# MCXN947_cm33_core0 register map
Vendor: nxp.com; File version: 1.0
CPU: CM33 r2p0, little endian, MPU, FPU, VTOR, 3 interrupt priority bits
Registers are 32-bit, read-write, reset 0x0 unless marked. A register's access mark holds for its fields unless they carry their own. Offsets are from the block's base; [hi:lo] are bit positions; {n}, {i} and the like mark numbered series; 'fields as' and 'values as' point back to an identical list.

## PKC0
Base 0x4002B000
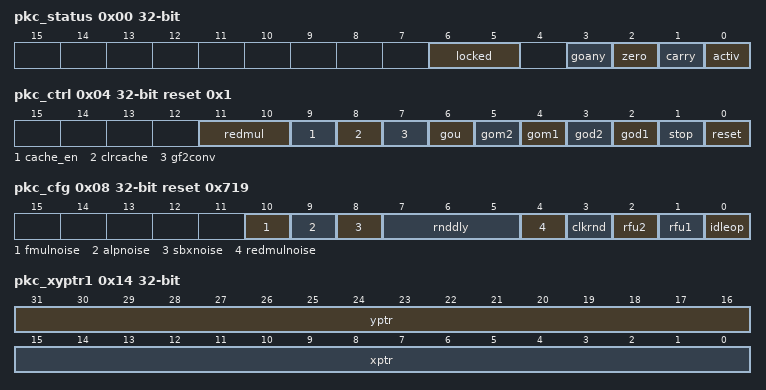
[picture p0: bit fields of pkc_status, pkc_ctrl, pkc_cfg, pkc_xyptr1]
0x00 pkc_status ro — Status register
  [6:5] locked — Parameter set locked: Indicates if parameter set is locked due to a pending calculation start or can be overwritten.
  [3] goany — Combined GO status flag: GOANY is set in case either PKC_CTRL.GOD1, GOD2, GOM1, GOM2 or GOU is set. The 1-to-0 transition of GOANY indicates that a calculation has been started and that a new GO bit can be set. If GOANY is cleared also all PKC_STATUS.LOCKED bits are cleared to indicate that the parameter set can be updated. GOANY is always '0' in case PKC_CTRL.RESET is set.
  [2] zero — Zero result flag: ZERO is set by the PKC at the end of a calculation in case the result of the calculation is equal zero. ZERO is updated for each PKC calculation mode, except for MUL1 (opcode 0x20) and MUL1_GF2 (opcode 0x24).
  [1] carry — Carry overflow flag: CARRY is set by the PKC at the end of a calculation in case
  [0] activ — PKC active: ACTIV=1 signals that a calculation is in progress or about to start. At the end of a calculation ACTIV is automatically reset to logic 0 in case no further GO bit is set. If the next PKC operation has been started by setting a GO bit during a calculation, ACTIV remains high. ACTIV is always '1' in case PKC_STATUS.GOANY is set. ACTIV is always '0' in case PKC_CTRL_RESET is set.
0x04 pkc_ctrl reset 0x1 — Control register
  [11:10] redmul — Reduced multiplier mode: REDMUL defines the operand width processed by the PKC coprocessor.
    0=fullsz (full size mode, 3 least significant bits of pointer and length are ignored, minimum supported length 0x0008); 1=VALUE_32bit (RFU Error Generated if selected); 2=VALUE_64bit (64-bit mode, 3 least significant bits of pointer and length are ignored, minimum supported length 0x0008); 3=VALUE_128bit (RFU Error Generated if selected)
  [9] cache_en — Enable universal pointer cache: If CACHE_EN=1 the cache for the universal pointer parameters is enabled. In case a parameter value is found in the cache (from a previous fetch) no DMA access is triggered. As such the amount of DMA accesses for the parameter fetch vary between 0 and 4. To further optimize the cache utilization not used parameters, e.g. XPTR for a plain addition (opcode 0x0A), could be defined equal to a used one (e.g. equal YPTR or RPTR) or a previously fetched parameter.
  [8] clrcache wo — Clear universal pointer cache: Invalidates the cache such that all previously fetched parameters are withdrawn and have to be fetched again via DMA accesses.
  [7] gf2conv — Convert to GF2 calculation modes: If GF2CONV is set operations are mapped to their GF(2) equivalent operation modes.
  [6] gou wo — Control bit to start pipe operation: If GOU is set PKC will start the pipe / L2 operation (parameter fetch & calculation) described in section 'PKC Universal Pointer Fetch Operation'.
  [5] gom2 wo — Control bit to start MC pattern using parameter set 2: If GOM2 is set PKC will start a MC pattern / L1 operation using parameter set 2 (PKC_MODE2, PKC_XYPTR2, PKC_ZRPTR2, PKC_LEN2).
  [4] gom1 wo — Control bit to start MC pattern using parameter set 1: If GOM1 is set PKC will start a MC pattern / L1 operation using parameter set 1 (PKC_MODE1, PKC_XYPTR1, PKC_ZRPTR1, PKC_LEN1).
  [3] god2 wo — Control bit to start direct operation using parameter set 2: If GOD2 is set PKC will start a direct / L0 operation using parameter set 2 (PKC_MODE2, PKC_XYPTR2, PKC_ZRPTR2, PKC_LEN2).
  [2] god1 wo — Control bit to start direct operation using parameter set 1: If GOD1 is set PKC will start a direct / L0 operation using parameter set 1 (PKC_MODE1, PKC_XYPTR1, PKC_ZRPTR1, PKC_LEN1).
  [1] stop — Freeze PKC calculation: STOP=1 freezes all PKC activity incl. RAM accesses and reduces the PKC power consumption to its minimum. The difference compared to the reset of the PKC is that a stopped calculation can be continued when STOP is released (reset to '0') again. The status flags are not affected by the STOP control bit.
  [0] reset — PKC reset control bit: RESET=1 enforces the PKC's reset state during which a calculation cannot be started and by which any ongoing calculation process is stopped. RESET can be set/cleared by the CPU in order to switch between PKC reset and calculation enable. RESET=1 is the default state after a chip reset.
0x08 pkc_cfg reset 0x719 — Configuration register
  [10] fmulnoise — Noise feature not available in this version (flag is don't care).
  [9] alpnoise — Noise feature not available in this version (flag is don't care).
  [8] sbxnoise — Noise feature not available in this version (flag is don't care).
  [7:5] rnddly — Random delay feature not available in this version (flag is don't care).
  [4] redmulnoise — Noise in reduced multiplier mode feature not available in this version (flag is don't care).
  [3] clkrnd — Clock randomization feature not available in this version (flag is don't care).
  [2] rfu2 — RFU
  [1] rfu1 — RFU
  [0] idleop — Idle operation feature not available in this version (flag is don't care).
0x10 pkc_mode1 — Mode register, parameter set 1
  [7:0] mode — Calculation Mode / MC Start address:
0x14 pkc_xyptr1 — X+Y pointer register, parameter set 1
  [31:16] yptr — Start address of Y operand in PKCRAM with byte granularity: Least significant bits are ignored depending on PKC_CTRL.REDMUL setting. Most significant bits are ignored depending on available PKCRAM size.
  [15:0] xptr — Start address of X operand in PKCRAM with byte granularity: Least significant bits are ignored depending on PKC_CTRL.REDMUL setting. Most significant bits are ignored depending on available PKCRAM size.
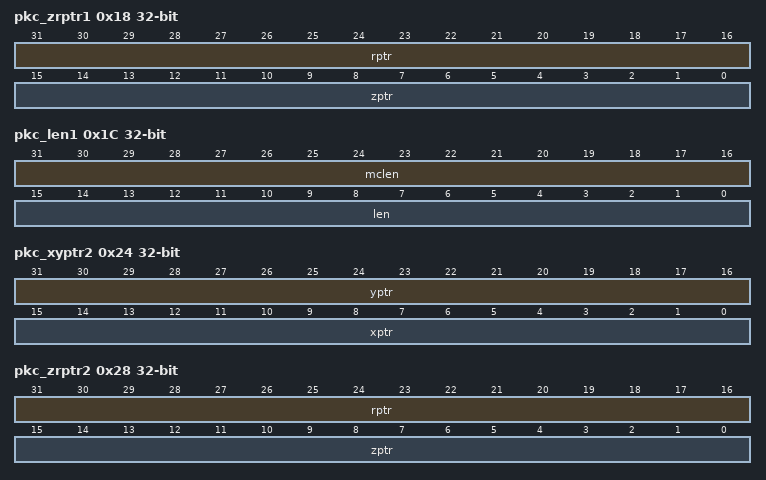
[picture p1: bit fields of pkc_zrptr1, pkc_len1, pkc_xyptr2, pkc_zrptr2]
0x18 pkc_zrptr1 — Z+R pointer register, parameter set 1
  [31:16] rptr — Start address of R result in PKCRAM with byte granularity: Least significant bits are ignored depending on PKC_CTRL.REDMUL setting. Most significant bits are ignored depending on available PKCRAM size.
  [15:0] zptr — Start address of Z operand in PKCRAM with byte granularity or constant for calculation modes using CONST:
0x1C pkc_len1 — Length register, parameter set 1
  [31:16] mclen — Loop counter for microcode pattern: MCLEN defines the length of the loop counter that can be used in L1 calculation mode, e.g. in MC opcode DecrTBNZ. For the hardcoded MC patterns Modular Multiplication (MC start address 0x00), Plain Multiplication (0x13), Plain Multiplication with Addition (0x1D) and Modular Reduction (0x33) MCLEN defines the length of the X operand in bytes.
  [15:0] len — Operand length: LEN defines the length of the operands and the result in bytes. The length of Y, Z and R depend furthermore on the selected calculation mode.
0x20 pkc_mode2 — Mode register, parameter set 2
  [7:0] mode — Calculation Mode / MC Start address:
0x24 pkc_xyptr2 — X+Y pointer register, parameter set 2
  fields as pkc_xyptr1
0x28 pkc_zrptr2 — Z+R pointer register, parameter set 2
  fields as pkc_zrptr1
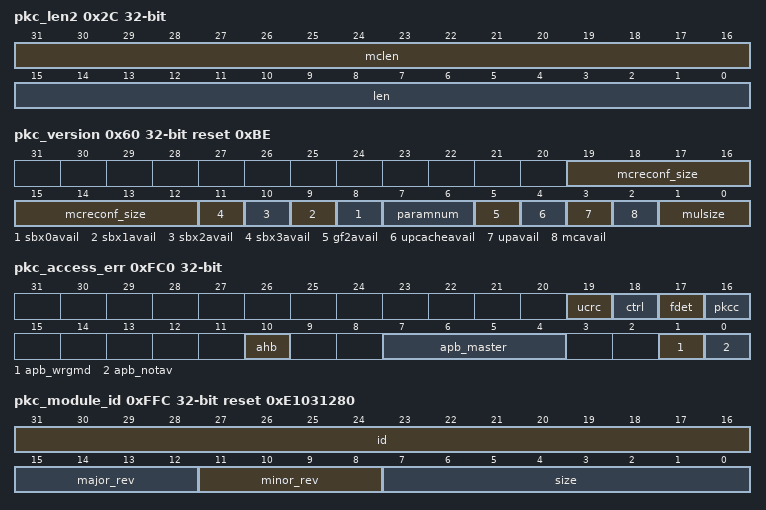
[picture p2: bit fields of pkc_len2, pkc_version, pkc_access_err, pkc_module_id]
0x2C pkc_len2 — Length register, parameter set 2
  [31:16] mclen — Loop counter for microcode pattern: MCLEN defines the length of the loop counter that can be used in L1 calculation mode, e.g. in MC opcode DecrTBNZ. For the hardcoded MC patterns Modular Multiplication (MC start address 0x00)
  [15:0] len — Operand length: LEN defines the length of the operands and the result in bytes. The length of Y, Z and R depend furthermore on the selected calculation mode.
0x40 pkc_uptr — Universal pointer FUP program
  [31:0] ptr — Pointer to start address of PKC FUP program: PKC_UPTR needs to be defined before starting a universal pointer PKC calculation (L2) via PKC_CTRL.GOU. The pointer address needs to be valid and the memory space the pointer addresses needs to be enabled for PKC access by the system. Otherwise a security alarm is triggered (PKC_ACCESS_ERR.AHB is set).
0x44 pkc_uptrt — Universal pointer FUP table
  [31:0] ptr — Pointer to start address of PKC FUP table: PKC_UPTRT needs to be defined before starting a universal pointer PKC calculation (L2) via PKC_CTRL.GOU. The pointer address needs to be valid and the memory space the pointer addresses needs to be enabled for PKC access by the system. Otherwise a security alarm is triggered (PKC_ACCESS_ERR.AHB is set).
0x48 pkc_ulen — Universal pointer length
  [7:0] len — Length of universal pointer calculation: PKC_ULEN defines how many FUP program entries shall be processed for one L2 calculation started via PKC_CTRL.GOU. The FUP program entries include L0 calculations, L1 calculations and CRC entries for FUP program integrity protection.
0x50 pkc_mcdata — MC pattern data interface
  [31:0] mcdata — Microcode read/write data: This IP version does not support flexible MC patterns (only hard coded ones). Any read or write access to PKC_MCDATA triggers a security alarm (PKC_ACCESS_ERR.CTRL is set).
0x60 pkc_version ro reset 0xBE
  [19:12] mcreconf_size — Size of reconfigurable MC table in bytes
  [n+8] sbx{n}avail (n=0..3) — SBX{n} operation is available
  [7:6] paramnum — Number of parameter sets for real calculation
  [5] gf2avail — GF2 calculation modes are available
  [4] upcacheavail — UP cache is available
  [3] upavail — UP feature (L2 calculation) is available
  [2] mcavail — MC feature (L1 calculation) is available
  [1:0] mulsize — native multiplier size and operand granularity
    1=VALUE_32b (32-bit multiplier); 2=VALUE_64b (64-bit multiplier); 3=VALUE_128b (128-bit multiplier)
0xFB0 pkc_soft_rst wo — Software reset
  [0] soft_rst — Write 1 to reset module (0 has no effect). All running and pending PKC calculation are stopped. All PKC SFRs are reset except PKC_ACCESS_ERR.
0xFC0 pkc_access_err ro — Access Error
  [19] ucrc — Error in L2 CRC check
  [18] ctrl — Error in PKC software control
  [17] fdet — Error due to error detection circuitry
  [16] pkcc — Error in PKC coprocessor kernel
  [10] ahb — AHB Error: invalid AHB access L2 Only
  [7:4] apb_master — APB Master that triggered first APB error (APB_WRGMD or APB_NOTAV)
  [1] apb_wrgmd — APB Error: Wrong access mode
  [0] apb_notav — APB Error: address not available
0xFC4 pkc_access_err_clr wo — Clear Access Error
  [0] err_clr — Write 1 to reset PKC_ACCESS_ERR SFR.
0xFD8 pkc_int_clr_enable wo — Interrupt enable clear
  [0] en_pdone — Write to clear PDONE interrupt enable flag (PKC_INT_ENABLE.EN_PDONE=0).
0xFDC pkc_int_set_enable wo — Interrupt enable set
  [0] en_pdone — Write to set PDONE interrupt enable flag (PKC_INT_ENABLE.EN_PDONE=1).
0xFE0 pkc_int_status ro — Interrupt status
  [0] int_pdone — End-of-computation status flag: INT_PDONE is set after EACH single PKC L0 or L1 calculation. In case of a universal pointer calculation (L2) INT_PDONE is set at the end of the pipe calculation when PKC_ULEN has been decremented to zero and the final PKC calculation has completed.
0xFE4 pkc_int_enable ro — Interrupt enable
  [0] en_pdone — PDONE interrupt enable flag: If EN_PDONE=1 an interrupt is triggered every time PKC_INT_STATUS.INT_PDONE is set. Otherwise the interrupt generation is suppressed.
0xFE8 pkc_int_clr_status wo — Interrupt status clear
  [0] int_pdone — Write to clear End-of-computation status flag (PKC_INT_STATUS.INT_PDONE=0).
0xFEC pkc_int_set_status wo — Interrupt status set
  [0] int_pdone — Write to set End-of-computation status flag (PKC_INT_STATUS.INT_PDONE=1) to trigger a PKC interrupt via software, e.g. for debug purposes.
0xFFC pkc_module_id ro reset 0xE1031280 — Module ID
  [31:16] id — Module ID
  [15:12] major_rev — Major revision
  [11:8] minor_rev — Minor revision
  [7:0] size — Address space of the IP
